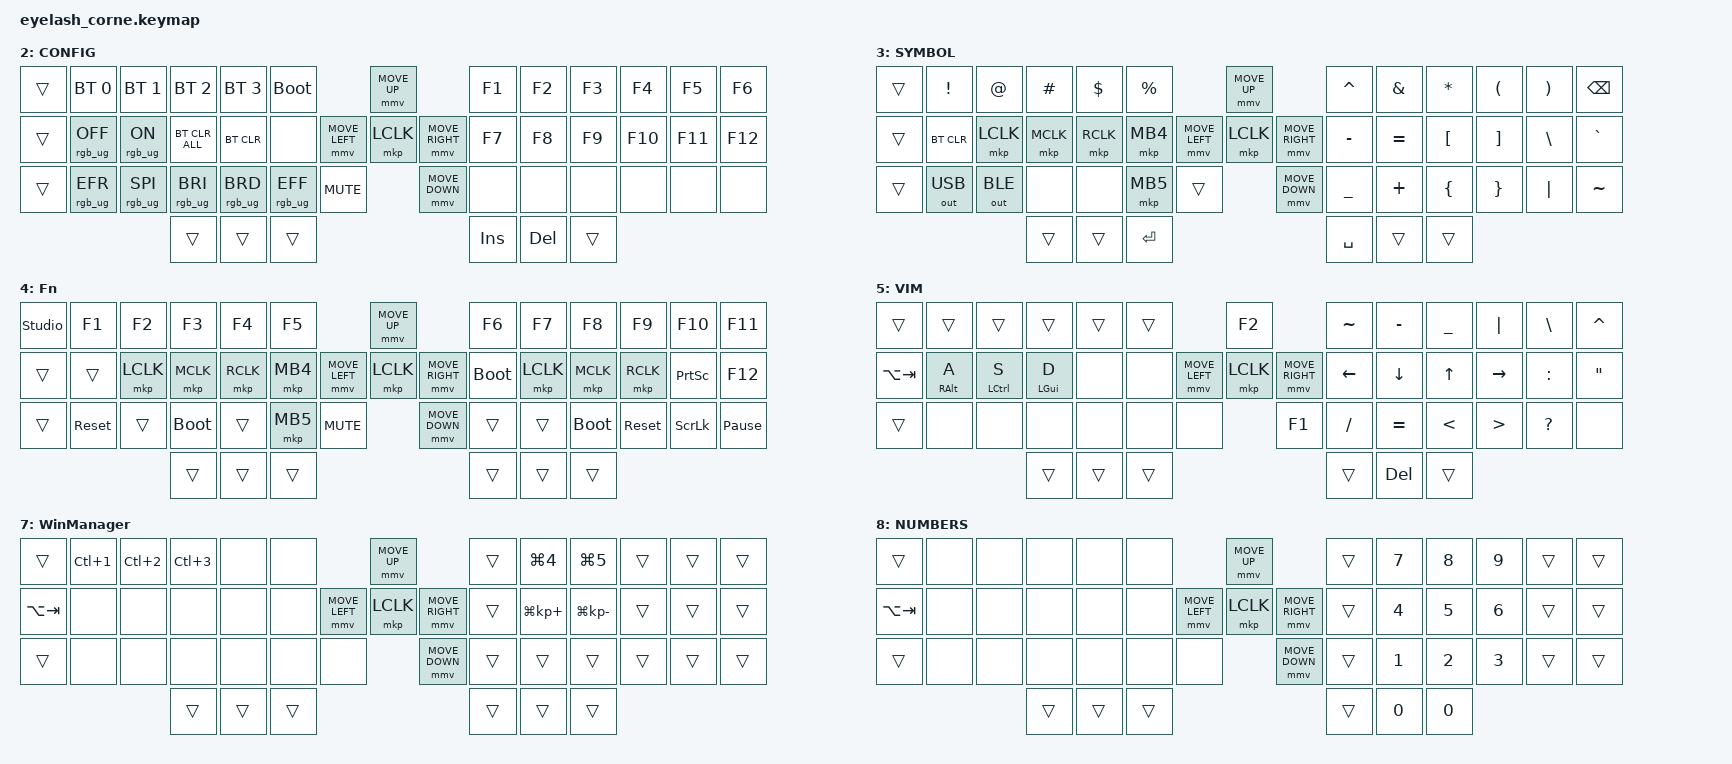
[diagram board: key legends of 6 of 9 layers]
#define ZMK_POINTING_DEFAULT_MOVE_VAL 1200  // 600
#define ZMK_POINTING_DEFAULT_SCRL_VAL 25   // 10

#include <input/processors.dtsi>
#include <zephyr/dt-bindings/input/input-event-codes.h>
#include <behaviors.dtsi>
#include <dt-bindings/zmk/bt.h>
#include <dt-bindings/zmk/keys.h>
#include <dt-bindings/zmk/outputs.h>
#include <dt-bindings/zmk/pointing.h>
#include <dt-bindings/zmk/rgb.h>

&mmv_input_listener { input-processors = <&zip_xy_scaler 2 1>; };

&msc_input_listener { input-processors = <&zip_scroll_scaler 2 1>; };

&msc {
    acceleration-exponent = <1>;      // 0
    time-to-max-speed-ms = <100>;       // 300
    delay-ms = <0>;                   // 0
};

&mmv {
    time-to-max-speed-ms = <500>;
    acceleration-exponent = <1>;
    trigger-period-ms = <16>;
};

&soft_off { hold-time-ms = <2000>; };

#define DEFAULT 0
#define COLEMAK 1
#define CONFIG 2
#define NUMPAD 3
#define WIN_MAN 4
#define VIM 5

#define ZOOM_IN &kp LG(KP_PLUS)
#define ZOOM_OUT &kp LG(KP_MINUS)
#define PLAY &kp C_PLAY_PAUSE


/ {
    behaviors {
        td0: td0 {
            compatible = "zmk,behavior-tap-dance";
            display-name = "Shift/Caps Lock Tap Dance";
            #binding-cells = <0>;
            bindings = <&kp LEFT_SHIFT>, <&kp CAPS>;
        };

        hm: homerow_mods {
            compatible = "zmk,behavior-hold-tap";
            #binding-cells = <2>;
            tapping-term-ms = <100>;
            quick-tap-ms = <105>;
            flavor = "tap-preferred";
            bindings = <&kp>, <&kp>;
        };

        ht: homerow_test_mods {
            compatible = "zmk,behavior-hold-tap";
            #binding-cells = <2>;
            tapping-term-ms = <125>;
            quick-tap-ms = <135>;
            flavor = "tap-preferred";
            bindings = <&kp>, <&kp>;
        };

        hh: homerow_hold {
            compatible = "zmk,behavior-hold-tap";
            #binding-cells = <2>;
            tapping-term-ms = <120>;
            quick-tap-ms = <120>;
            flavor = "balanced";
            bindings = <&mo>, <&kp>;
        };

        hl: homerow_low_mods {
            compatible = "zmk,behavior-hold-tap";
            #binding-cells = <2>;
            tapping-term-ms = <180>;
            quick-tap-ms = <170>;
            flavor = "tap-preferred";
            bindings = <&kp>, <&kp>;
        };

    };

    rgb_encoder: rgb_encoder {
        compatible = "zmk,behavior-sensor-rotate";
        #sensor-binding-cells = <0>;
        bindings = <&rgb_ug RGB_BRI>, <&rgb_ug RGB_BRD>;
    };

    scroll_encoder: scroll_encoder {
        compatible = "zmk,behavior-sensor-rotate";
        #sensor-binding-cells = <0>;
        bindings = <&msc SCRL_DOWN>, <&msc SCRL_UP>;

        tap-ms = <100>;
    };


    combos {
        compatible = "zmk,combos";

        softoff {
            bindings = <&soft_off>;
            key-positions = <1 15 29>;
        };
    };

    keymap {
        compatible = "zmk,keymap";

        default_layer {
            display-name = "QWERTY";
            bindings = <
&kp ESC    &kp Q         &kp W       &kp E      &kp R   &kp T                               &kp C_VOLUME_UP                &kp Y        &kp U   &kp I      &kp O       &kp P      &kp BSPC
&hh 8 TAB  &hl RALT A    &ht LCTRL S &ht LGUI D &hh 5 F &kp G                     &kp C_PREV  PLAY  &kp C_NEXT  &kp H        &hh 6 J &hm LGUI K &hm LCTRL L &hl RALT SEMI &kp SQT
&mo 2      &mt LSHIFT Z  &kp X       &kp C      &kp V   &kp B        &kp SPACE              &kp C_VOLUME_DOWN              &kp N        &kp M  &kp COMMA   &kp DOT     &mt RSHIFT SLASH   &tog 1
                            &kp PRINTSCREEN  &kp ESC  &kp ENTER                                               &kp SPACE  &kp BSPC  &kp RS(LA(LG(M)))
            >;

            sensor-bindings = <&inc_dec_kp C_VOLUME_UP C_VOLUME_DOWN>;
        };

        // layer 1
        colemak_layer {
            display-name = "COLEMAK";
            bindings = <
&kp ESC     &kp Q  &kp W &kp F        &kp P       &kp B                                    &kp C_VOLUME_UP                  &kp J        &kp L   &kp U      &kp Y       &kp SEMI                   &kp BSPC
&hh 8 TAB   &hl RALT A   &hm LCTRL R  &hm LGUI S  &hh 5 T &kp G                    &kp C_PREV  &kp C_PLAY_PAUSE  &kp C_NEXT  &kp M        &hh 6 N &hm LGUI E &hm LCTRL I &hh 7 O              &kp SQT
&mo 2       &mt LSHIFT Z &kp X        &kp C       &kp D   &kp V   &kp ENTER              &kp C_VOLUME_DOWN                  &kp K        &kp H   &kp COMMA  &kp DOT     &mt RIGHT_SHIFT SLASH   &tog 1
                                              &kp PRINTSCREEN  &kp ESC  &kp ENTER                                              &kp SPACE  &kp BSPC  &kp RS(LA(LG(M)))
            >;
            sensor-bindings = <&inc_dec_kp C_VOLUME_UP C_VOLUME_DOWN>;
        };

        // layer 2
        lower_layer {
            display-name = "CONFIG";
            bindings = <
&trans  &bt BT_SEL 0    &bt BT_SEL 1    &bt BT_SEL 2    &bt BT_SEL 3  &bootloader                           &mmv MOVE_UP                     &kp F1  &kp F2 &kp F3 &kp F4 &kp F5 &kp F6
&trans  &rgb_ug RGB_OFF &rgb_ug RGB_ON  &bt BT_CLR_ALL  &bt BT_CLR    &none                   &mmv MOVE_LEFT  &mkp LCLK       &mmv MOVE_RIGHT  &kp F7  &kp F8 &kp F9 &kp F10 &kp F11 &kp F12
&trans  &rgb_ug RGB_EFR &rgb_ug RGB_SPI &rgb_ug RGB_BRI &rgb_ug RGB_BRD &rgb_ug RGB_EFF &kp C_MUTE      &mmv MOVE_DOWN                   &none  &none &none &none &none &none
                                         &trans        &trans        &trans                                                          &kp INS    &kp DEL  &trans
            >;
            sensor-bindings = <&scroll_encoder>;
        };

        // layer 3
        raise_layer {
            display-name = "SYMBOL";
            bindings = <
&trans  &kp EXCL      &kp AT        &kp HASH   &kp DLLR   &kp PRCNT                           &mmv MOVE_UP                     &kp CARET  &kp AMPS   &kp ASTRK  &kp LPAR  &kp RPAR  &kp BSPC
&trans  &bt BT_CLR    &mkp LCLK     &mkp MCLK  &mkp RCLK  &mkp MB4            &mmv MOVE_LEFT  &mkp LCLK       &mmv MOVE_RIGHT  &kp MINUS  &kp EQUAL  &kp LBKT   &kp RBKT  &kp BSLH  &kp GRAVE
&trans  &out OUT_USB  &out OUT_BLE  &none      &none      &mkp MB5  &trans                    &mmv MOVE_DOWN                   &kp UNDER  &kp PLUS   &kp LBRC   &kp RBRC  &kp PIPE  &kp TILDE
                                    &trans     &trans     &kp ENTER                                                            &kp SPACE    &trans     &trans
            >;

            sensor-bindings = <&scroll_encoder>;
        };

        // layer 4
        function_layer {
            display-name = "Fn";
            bindings = <
&studio_unlock   &kp F1      &kp F2      &kp F3       &kp F4     &kp F5                                  &mmv MOVE_UP                     &kp F6       &kp F7     &kp F8       &kp F9      &kp F10          &kp F11
&trans  &trans      &mkp LCLK   &mkp MCLK    &mkp RCLK  &mkp MB4                &mmv MOVE_LEFT  &mkp LCLK       &mmv MOVE_RIGHT  &bootloader  &mkp LCLK  &mkp MCLK    &mkp RCLK   &kp PRINTSCREEN  &kp F12
&trans  &sys_reset  &trans      &bootloader  &trans     &mkp MB5  &kp C_MUTE                    &mmv MOVE_DOWN                   &trans       &trans     &bootloader  &sys_reset  &kp SCROLLLOCK   &kp PAUSE_BREAK
                                &trans      &trans      &trans                                                                   &trans       &trans     &trans
            >;
            sensor-bindings = <&scroll_encoder>;
        };

        // layer 5
        vim_layer {
            display-name = "VIM";
            bindings = <
&trans       &trans      &trans     &trans      &trans  &trans                      &kp F2                         &kp TILDE  &kp MINUS  &kp UNDER   &kp PIPE   &kp BACKSLASH  &kp CARET
&kp LA(TAB) &hl RALT A  &hm LCTRL S &hm LGUI D  &none   &none        &mmv MOVE_LEFT &mkp LCLK       &mmv MOVE_RIGHT &kp LEFT   &kp DOWN   &kp UP      &kp RIGHT  &kp COLON      &kp DOUBLE_QUOTES
&trans      &none       &none       &none       &none   &none &none                 &kp F1                         &kp SLASH  &kp EQUAL  &kp LESS_THAN  &kp GREATER_THAN   &kp QUESTION &none
                                &trans      &trans      &trans                                                                   &trans       &kp DELETE     &trans
            >;
            sensor-bindings = <&scroll_encoder>;
        };

        // layer 6
        symbols_layer {
            display-name = "Symbols";
            bindings = <
&trans      &kp EXCLAMATION &kp AT_SIGN &kp LPAR         &kp RPAR          &kp PERCENT                      &mmv MOVE_UP              &trans     &trans      &kp LG(N4) &kp LG(N5)  &trans    &trans
&kp LA(TAB) &kp AMPERSAND &kp DOLLAR  &kp LEFT_BRACE   &kp RIGHT_BRACE   &kp ASTERISK        &mmv MOVE_LEFT &mkp LCLK &mmv MOVE_RIGHT &trans     &trans      ZOOM_IN    ZOOM_OUT  &trans    &trans
&trans      &kp HASH      &kp GRAVE   &kp LEFT_BRACKET &kp RIGHT_BRACKET &kp PLUS                       &mmv MOVE_DOWN                &trans     &trans      &trans     &trans  &trans    &trans
                &trans      &trans      &trans                                                                   &trans       &trans     &trans
            >;
            sensor-bindings = <&scroll_encoder>;
        };

        // layer 7
        win_layer {
            display-name = "WinManager";
            bindings = <
&trans      &kp LC(N1)  &kp LC(N2)  &kp LC(N3)  &none &none                      &mmv MOVE_UP               &trans     &kp LG(N4)       &kp LG(N5)          &trans  &trans  &trans
&kp LA(TAB) &none       &none       &none       &none &none        &mmv MOVE_LEFT &mkp LCLK &mmv MOVE_RIGHT &trans     &kp LG(KP_PLUS)  &kp LG(KP_MINUS)     &trans  &trans  &trans
&trans      &none       &none       &none       &none &none &none                       &mmv MOVE_DOWN      &trans     &trans           &trans              &trans  &trans  &trans
                &trans      &trans      &trans                                                              &trans       &trans    &trans
            >;
            sensor-bindings = <&scroll_encoder>;
        };

        // layer 8
        num_layer {
            display-name = "NUMBERS";
            bindings = <
&trans      &none  &none  &none  &none &none                      &mmv MOVE_UP                          &trans  &kp N7  &kp N8 &kp N9  &trans  &trans
&kp LA(TAB) &none  &none       &none       &none &none        &mmv MOVE_LEFT &mkp LCLK &mmv MOVE_RIGHT  &trans  &kp N4  &kp N5 &kp N6  &trans  &trans
&trans      &none  &none       &none       &none &none &none                       &mmv MOVE_DOWN       &trans  &kp N1  &kp N2 &kp N3  &trans  &trans
                &trans      &trans      &trans                                                      &trans      &kp N0    &kp N0
            >;
            sensor-bindings = <&scroll_encoder>;
        };



    };
};

